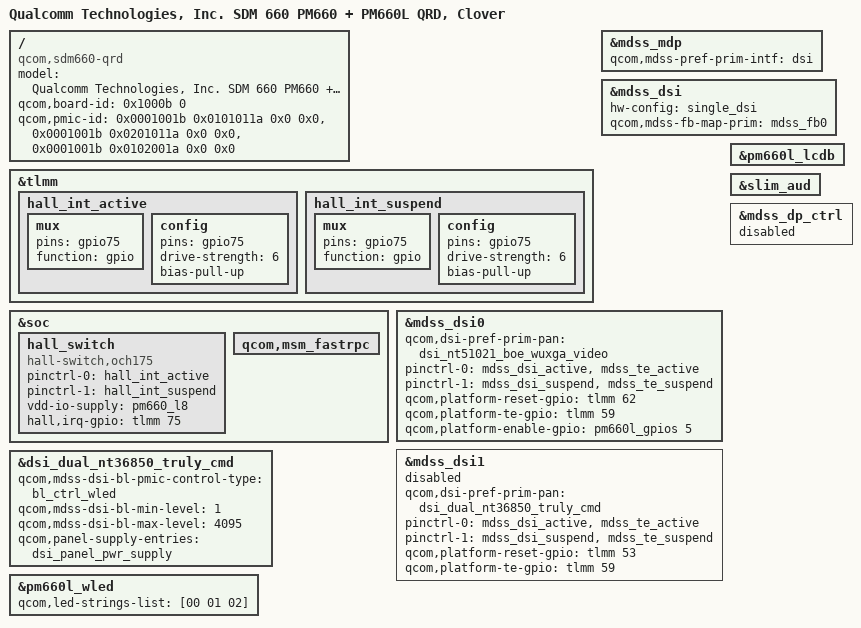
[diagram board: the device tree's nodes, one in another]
/* Copyright (c) 2016-2017, The Linux Foundation. All rights reserved.
 * Copyright (C) 2019 XiaoMi, Inc.
 *
 * This program is free software; you can redistribute it and/or modify
 * it under the terms of the GNU General Public License version 2 and
 * only version 2 as published by the Free Software Foundation.
 *
 * This program is distributed in the hope that it will be useful,
 * but WITHOUT ANY WARRANTY; without even the implied warranty of
 * MERCHANTABILITY or FITNESS FOR A PARTICULAR PURPOSE.  See the
 * GNU General Public License for more details.
 */


/dts-v1/;

#include "sdm660.dtsi"
#include "sdm660-qrd.dtsi"

/ {
	model = "Qualcomm Technologies, Inc. SDM 660 PM660 + PM660L QRD, Clover";
	compatible = "qcom,sdm660-qrd", "qcom,sdm660", "qcom,qrd";
	qcom,board-id = <0x1000b 0>;
	qcom,pmic-id = <0x0001001b 0x0101011a 0x0 0x0>,
			<0x0001001b 0x0201011a 0x0 0x0>,
			<0x0001001b 0x0102001a 0x0 0x0>;
};

&tlmm {
	hall_int_active:hall_int_active {
		mux {
		          pins = "gpio75";
		          function = "gpio";
		};
		config{
		          pins = "gpio75";
	                  drive-strength = <6>;
	                  bias-pull-up;
	            };
        };
	hall_int_suspend: hall_int_suspend {
		mux {
		          pins = "gpio75";
		          function = "gpio";
		};
		config{
		          pins = "gpio75";
		          drive-strength = <6>;
		          bias-pull-up;
		};
    };
};

&soc {
	hall_switch {

	    compatible = "hall-switch,och175";
	    pinctrl-names = "hall_active","hall_suspend";
	    pinctrl-0 = <&hall_int_active>;
	    pinctrl-1 = <&hall_int_suspend>;
	    //interrupt-parent = <&msm_gpio>;
	    //interrupts = <0 107 3>;
	    vdd-io-supply= <&pm660_l8>;
	    interrupt-names = "hall_irq";
	    hall,irq-gpio = <&tlmm 75 0x0>;
	};

	qcom,msm_fastrpc {
		/delete-property/ qcom,fastrpc-adsp-sensors-pdr;
	};
};

&mdss_mdp {
	qcom,mdss-pref-prim-intf = "dsi";
};

&mdss_dsi {
	hw-config = "single_dsi";
	qcom,mdss-fb-map-prim = <&mdss_fb0>;
};

&mdss_dsi0 {
	qcom,dsi-pref-prim-pan = <&dsi_nt51021_boe_wuxga_video>;
	pinctrl-names = "mdss_default", "mdss_sleep";
	pinctrl-0 = <&mdss_dsi_active &mdss_te_active>;
	pinctrl-1 = <&mdss_dsi_suspend &mdss_te_suspend>;
	qcom,platform-reset-gpio = <&tlmm 62 0>;
	qcom,platform-te-gpio = <&tlmm 59 0>;
	qcom,platform-enable-gpio = <&pm660l_gpios 5 0>; /* VDD3V3 LDO Enable */
};

&mdss_dsi1 {
	status = "disabled";
	qcom,dsi-pref-prim-pan = <&dsi_dual_nt36850_truly_cmd>;
	pinctrl-names = "mdss_default", "mdss_sleep";
	pinctrl-0 = <&mdss_dsi_active &mdss_te_active>;
	pinctrl-1 = <&mdss_dsi_suspend &mdss_te_suspend>;
	qcom,platform-reset-gpio = <&tlmm 53 0>;
	qcom,platform-te-gpio = <&tlmm 59 0>;
};

&dsi_dual_nt36850_truly_cmd {
	qcom,mdss-dsi-bl-pmic-control-type = "bl_ctrl_wled";
	qcom,mdss-dsi-bl-min-level = <1>;
	qcom,mdss-dsi-bl-max-level = <4095>;
	qcom,panel-supply-entries = <&dsi_panel_pwr_supply>;
};

&pm660l_wled {
	qcom,led-strings-list = [00 01 02];
	status = "ok";
};

&pm660l_lcdb {
	status = "ok";
};

&slim_aud {
	/delete-node/wcd934x_cdc;
};

&soc {
	/delete-node/sound-tavil;
};

/* Battery Data Reset
drop qrd -> fg-gen3-batterydata-qrd-skuk-4v4-3000mah
*/
/delete-node/ &qrd_batterydata;

#include "xiaomi/clover.dtsi"

&mdss_dp_ctrl {
    status = "disabled";
};

&tlmm {
	/delete-node/ pmx_ts_rst_active;
	/delete-node/ pmx_ts_rst_suspend;
};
